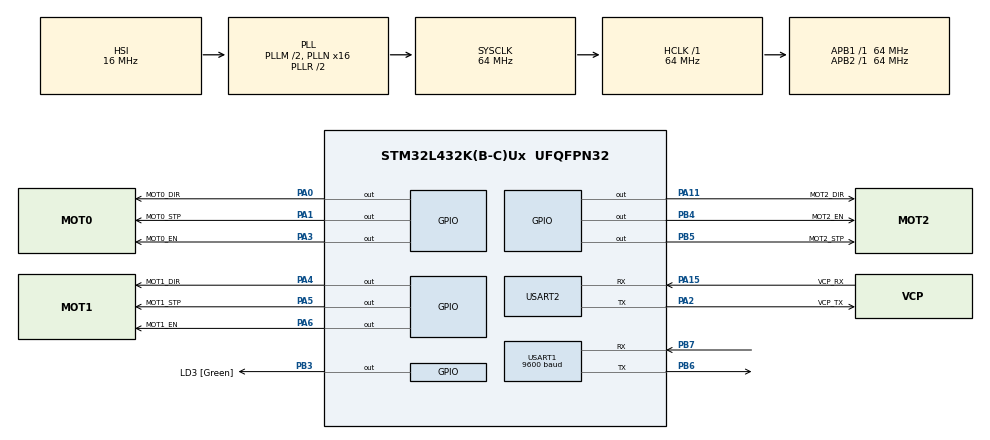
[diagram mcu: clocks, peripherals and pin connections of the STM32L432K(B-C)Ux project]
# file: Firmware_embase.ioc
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Dma.Request0=USART2_TX
Dma.Request1=USART1_TX
Dma.USART1_TX.1.Direction=DMA_MEMORY_TO_PERIPH
Dma.USART1_TX.1.Instance=DMA1_Channel4
Dma.USART1_TX.1.MemDataAlignment=DMA_MDATAALIGN_BYTE
Dma.USART1_TX.1.MemInc=DMA_MINC_ENABLE
Dma.USART1_TX.1.Mode=DMA_NORMAL
Dma.USART1_TX.1.PeriphDataAlignment=DMA_PDATAALIGN_BYTE
Dma.USART1_TX.1.PeriphInc=DMA_PINC_DISABLE
Dma.USART1_TX.1.Priority=DMA_PRIORITY_HIGH
Dma.USART2_TX.0.Direction=DMA_MEMORY_TO_PERIPH
Dma.USART2_TX.0.Instance=DMA1_Channel7
Dma.USART2_TX.0.MemDataAlignment=DMA_MDATAALIGN_BYTE
Dma.USART2_TX.0.MemInc=DMA_MINC_ENABLE
Dma.USART2_TX.0.Mode=DMA_NORMAL
Dma.USART2_TX.0.PeriphDataAlignment=DMA_PDATAALIGN_BYTE
Dma.USART2_TX.0.PeriphInc=DMA_PINC_DISABLE
Dma.USART2_TX.0.Priority=DMA_PRIORITY_HIGH
Mcu.Family=STM32L4
Mcu.Name=STM32L432K(B-C)Ux
Mcu.Package=UFQFPN32
NVIC.DMA1_Channel4_IRQn=true\:0\:0\:false\:false\:true\:false\:true\:true
NVIC.DMA1_Channel7_IRQn=true\:0\:0\:false\:false\:true\:false\:true\:true
NVIC.PriorityGroup=NVIC_PRIORITYGROUP_4
NVIC.TIM2_IRQn=true\:0\:0\:false\:false\:true\:true\:true\:true
NVIC.TIM6_DAC_IRQn=true\:0\:0\:false\:false\:true\:true\:true\:true
NVIC.TIM7_IRQn=true\:0\:0\:false\:false\:true\:true\:true\:true
NVIC.USART1_IRQn=true\:0\:0\:false\:false\:true\:true\:true\:true
NVIC.USART2_IRQn=true\:0\:0\:false\:false\:true\:true\:true\:true
PA0.GPIO_Label=MOT0_DIR
PA0.Signal=GPIO_Output
PA1.GPIO_Label=MOT0_STP
PA1.Signal=GPIO_Output
PA11.GPIO_Label=MOT2_DIR
PA11.Signal=GPIO_Output
PA13\ (JTMS-SWDIO).GPIO_Label=SWDIO
PA13\ (JTMS-SWDIO).Mode=Serial_Wire
PA13\ (JTMS-SWDIO).Signal=SYS_JTMS-SWDIO
PA14\ (JTCK-SWCLK).GPIO_Label=SWCLK
PA14\ (JTCK-SWCLK).Mode=Serial_Wire
PA14\ (JTCK-SWCLK).Signal=SYS_JTCK-SWCLK
PA15\ (JTDI).GPIO_Label=VCP_RX
PA15\ (JTDI).Mode=Asynchronous
PA15\ (JTDI).Signal=USART2_RX
PA2.GPIO_Label=VCP_TX
PA2.Mode=Asynchronous
PA2.Signal=USART2_TX
PA3.GPIO_Label=MOT0_EN
PA3.Signal=GPIO_Output
PA4.GPIO_Label=MOT1_DIR
PA4.Signal=GPIO_Output
PA5.GPIO_Label=MOT1_STP
PA5.Signal=GPIO_Output
PA6.GPIO_Label=MOT1_EN
PA6.Signal=GPIO_Output
PB3\ (JTDO-TRACESWO).GPIO_Label=LD3 [Green]
PB3\ (JTDO-TRACESWO).Signal=GPIO_Output
PB4\ (NJTRST).GPIO_Label=MOT2_EN
PB4\ (NJTRST).Signal=GPIO_Output
PB5.GPIO_Label=MOT2_STP
PB5.Signal=GPIO_Output
PB6.Mode=Asynchronous
PB6.Signal=USART1_TX
PB7.Mode=Asynchronous
PB7.Signal=USART1_RX
PC14-OSC32_IN\ (PC14).Signal=RCC_OSC32_IN
PC15-OSC32_OUT\ (PC15).Signal=RCC_OSC32_OUT
ProjectManager.HeapSize=0x200
ProjectManager.StackSize=0x400
ProjectManager.TargetToolchain=STM32CubeIDE
RCC.ADCFreq_Value=32000000
RCC.AHBFreq_Value=64000000
RCC.APB1Freq_Value=64000000
RCC.APB1TimFreq_Value=64000000
RCC.APB2Freq_Value=64000000
RCC.APB2TimFreq_Value=64000000
RCC.CortexFreq_Value=64000000
RCC.HCLKFreq_Value=64000000
RCC.HSE_VALUE=8000000
RCC.HSI16_VALUE=16000000
RCC.HSI48_VALUE=48000000
RCC.HSI_VALUE=16000000
RCC.LSE_VALUE=32768
RCC.MSI_VALUE=4000000
RCC.PLLM=2
RCC.PLLMUL=RCC_PLLMUL_4
RCC.PLLN=16
RCC.PLLSourceVirtual=RCC_PLLSOURCE_HSI
RCC.SYSCLKFreq_VALUE=64000000
RCC.SYSCLKSource=RCC_SYSCLKSOURCE_PLLCLK
RCC.USBFreq_Value=32000000
RCC.VCOOutputFreq_Value=128000000
TIM2.Period=65535
TIM2.Prescaler=63
TIM6.Prescaler=63
TIM7.Prescaler=63
USART1.BaudRate=9600
USART1.VirtualMode-Asynchronous=VM_ASYNC
USART2.VirtualMode-Asynchronous=VM_ASYNC
VP_TIM2_VS_ClockSourceINT.Mode=Internal
VP_TIM6_VS_ClockSourceINT.Mode=Enable_Timer
VP_TIM7_VS_ClockSourceINT.Mode=Enable_Timer
board=NUCLEO-L432KC

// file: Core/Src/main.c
/* USER CODE BEGIN Header */
/**
  ******************************************************************************
  * @file           : main.c
  * @brief          : Main program body
  ******************************************************************************
  * @attention
  *
  * Copyright (c) 2024 STMicroelectronics.
  * All rights reserved.
  *
  * This software is licensed under terms that can be found in the LICENSE file
  * in the root directory of this software component.
  * If no LICENSE file comes with this software, it is provided AS-IS.
  *
  ******************************************************************************
  */
/* USER CODE END Header */
#include "main.h"
#include "dma.h"
#include "tim.h"
#include "usart.h"
#include "gpio.h"

/* USER CODE BEGIN Includes */
#include "Motors.h"
#include "CommandHandler.h"
#include "HC06.h"
/* USER CODE END Includes */

/* USER CODE BEGIN PV */
extern uint8_t command_buffer[];
/* USER CODE END PV */

void SystemClock_Config(void);

int main(void)
{

  /* USER CODE BEGIN 1 */
	MotorDirection_t dirs[3] = {DIR_FORWARD, DIR_FORWARD, DIR_BACKWARD};
	int64_t step_counts[3] = {-1, -1, -1};
	uint32_t periods[3] = {10000, 10000, 10000};

  /* USER CODE END 1 */

  /* MCU Configuration--------------------------------------------------------*/

  /* Reset of all peripherals, Initializes the Flash interface and the Systick. */
  HAL_Init();

  /* Configure the system clock */
  SystemClock_Config();

  /* Initialize all configured peripherals */
  MX_GPIO_Init();
  MX_DMA_Init();
  MX_USART2_UART_Init();
  MX_TIM2_Init();
  MX_TIM6_Init();
  MX_TIM7_Init();
  MX_USART1_UART_Init();
  /* USER CODE BEGIN 2 */
  HC06_TestPresence();
  // Motors_Init();
  // HAL_UART_Receive_IT(&huart2, &(command_buffer[0]), 1);

  // printToUart(COMMAND_UART_HANDLE_PTR, (uint8_t *) "Init OK\n");
  // Motors_SetSpeedAll(dirs, periods, step_counts);
  /* USER CODE END 2 */

  /* Infinite loop */
  while (1)
  {

  }
}

void SystemClock_Config(void)
{
  RCC_OscInitTypeDef RCC_OscInitStruct = {0};
  RCC_ClkInitTypeDef RCC_ClkInitStruct = {0};

  /** Configure the main internal regulator output voltage
  */
  if (HAL_PWREx_ControlVoltageScaling(PWR_REGULATOR_VOLTAGE_SCALE1) != HAL_OK)
  {
    Error_Handler();
  }

  /** Initializes the RCC Oscillators according to the specified parameters
  * in the RCC_OscInitTypeDef structure.
  */
  RCC_OscInitStruct.OscillatorType = RCC_OSCILLATORTYPE_HSI;
  RCC_OscInitStruct.HSIState = RCC_HSI_ON;
  RCC_OscInitStruct.HSICalibrationValue = RCC_HSICALIBRATION_DEFAULT;
  RCC_OscInitStruct.PLL.PLLState = RCC_PLL_ON;
  RCC_OscInitStruct.PLL.PLLSource = RCC_PLLSOURCE_HSI;
  RCC_OscInitStruct.PLL.PLLM = 2;
  RCC_OscInitStruct.PLL.PLLN = 16;
  RCC_OscInitStruct.PLL.PLLP = RCC_PLLP_DIV7;
  RCC_OscInitStruct.PLL.PLLQ = RCC_PLLQ_DIV2;
  RCC_OscInitStruct.PLL.PLLR = RCC_PLLR_DIV2;
  if (HAL_RCC_OscConfig(&RCC_OscInitStruct) != HAL_OK)
  {
    Error_Handler();
  }

  /** Initializes the CPU, AHB and APB buses clocks
  */
  RCC_ClkInitStruct.ClockType = RCC_CLOCKTYPE_HCLK|RCC_CLOCKTYPE_SYSCLK
                              |RCC_CLOCKTYPE_PCLK1|RCC_CLOCKTYPE_PCLK2;
  RCC_ClkInitStruct.SYSCLKSource = RCC_SYSCLKSOURCE_PLLCLK;
  RCC_ClkInitStruct.AHBCLKDivider = RCC_SYSCLK_DIV1;
  RCC_ClkInitStruct.APB1CLKDivider = RCC_HCLK_DIV1;
  RCC_ClkInitStruct.APB2CLKDivider = RCC_HCLK_DIV1;

  if (HAL_RCC_ClockConfig(&RCC_ClkInitStruct, FLASH_LATENCY_3) != HAL_OK)
  {
    Error_Handler();
  }
}

/* USER CODE BEGIN 4 */

//////// TIMER INTERRUPTS ///////
void HAL_TIM_PeriodElapsedCallback(TIM_HandleTypeDef* htim)
{
	// Callback for motor control (Impulses for the stepper)
	Motors_TimerITCallback(htim);
}

void HAL_UART_RxCpltCallback(UART_HandleTypeDef * huart)
{
	if (huart->Instance == COMMAND_UART_HANDLE_PTR->Instance)
	{
		Commands_RxCallback(huart);
	}
}

/* USER CODE END 4 */

void Error_Handler(void)
{
  __disable_irq();
  while (1)
  {
  }
}
